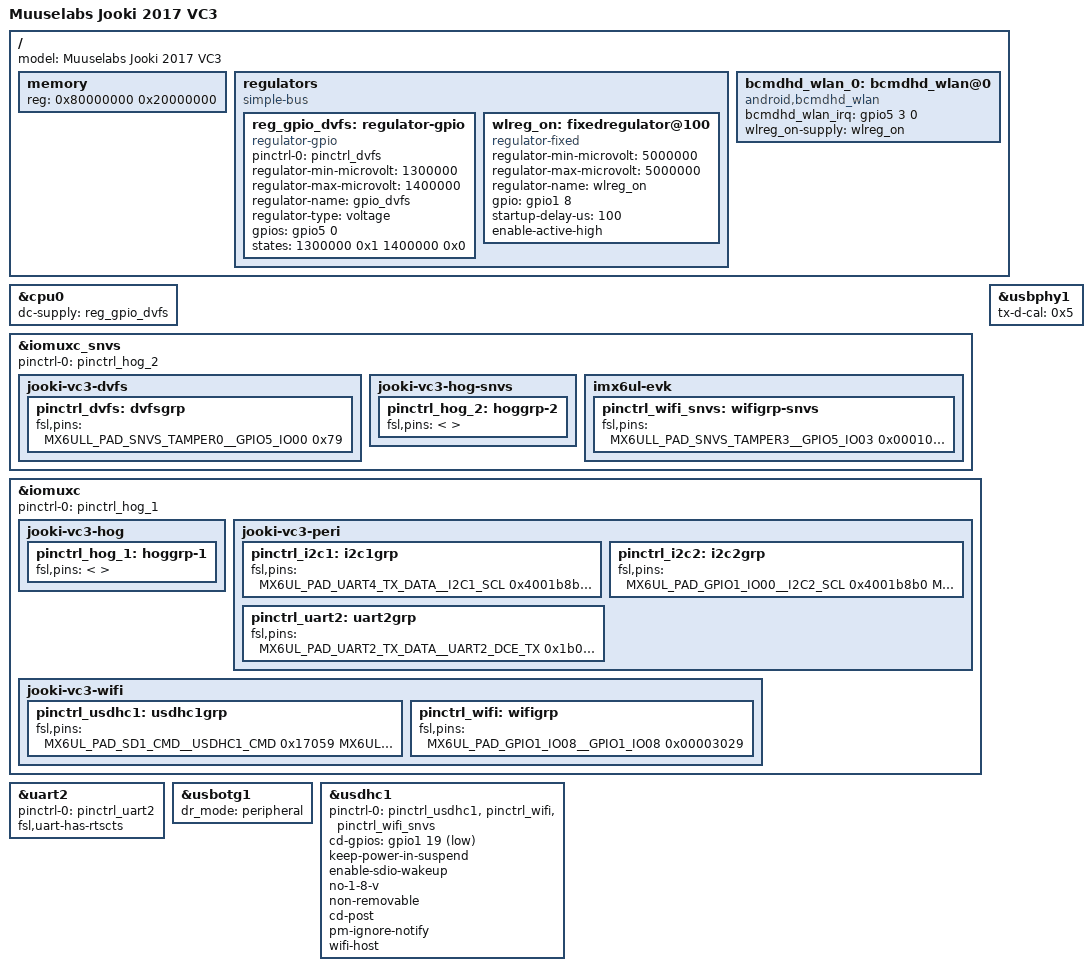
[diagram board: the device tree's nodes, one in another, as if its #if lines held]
/*
 * Copyright (C) 2016 Freescale Semiconductor, Inc.
 * Copyright (C) 2017, Muuselabs NV/SA
 *
 * This program is free software; you can redistribute it and/or modify
 * it under the terms of the GNU General Public License version 2 as
 * published by the Free Software Foundation.
 */


/dts-v1/;

#include <dt-bindings/input/input.h>
#include "imx6ull.dtsi"

#include "ml-jooki-common.dtsi"

/ {
	model = "Muuselabs Jooki 2017 VC3";
	
	// NOTE: the amount of memory can be board-specific
	memory {
		reg = <0x80000000 0x20000000>;
	};
};

/* Dynamic Voltage and Frequency Scaling
 * requires a proper spec of the reg_gpio_dvfs
 * which is board specific in its GPIO assignment
 */
/ {
	regulators {
		compatible = "simple-bus";
		#address-cells = <1>;
		#size-cells = <0>;
		
		reg_gpio_dvfs: regulator-gpio {
			compatible = "regulator-gpio";
			pinctrl-names = "default";
			pinctrl-0 = <&pinctrl_dvfs>;
			regulator-min-microvolt = <1300000>;
			regulator-max-microvolt = <1400000>;
			regulator-name = "gpio_dvfs";
			regulator-type = "voltage";
			// PP: crosschecked sch VC3.0  20170714
			gpios = <&gpio5 0 GPIO_ACTIVE_HIGH>;  
			states = <1300000 0x1 1400000 0x0>;
		};
	};
};

&cpu0 {
	dc-supply = <&reg_gpio_dvfs>;
};

&iomuxc_snvs {
	jooki-vc3-dvfs {
		pinctrl_dvfs: dvfsgrp {
			fsl,pins = <
			MX6ULL_PAD_SNVS_TAMPER0__GPIO5_IO00      0x79 /* PP: crosschecked sch VC3.0  20170714 */
			>;
		};
	};
};

/* HOG / GPIO
 * TODO: what does this stand for?
 */

&iomuxc {
	pinctrl-names = "default";
	pinctrl-0 = <&pinctrl_hog_1>;
	jooki-vc3-hog {
		pinctrl_hog_1: hoggrp-1 {
			fsl,pins = <
			>;
		};
	};
};

&iomuxc_snvs {
	pinctrl-names = "default_snvs";
	pinctrl-0 = <&pinctrl_hog_2>;
	jooki-vc3-hog-snvs {
		pinctrl_hog_2: hoggrp-2 {
			fsl,pins = <
			>;
		};
	};
};

/* Serial interfaces
 */
&iomuxc {
	jooki-vc3-peri {
		pinctrl_i2c1: i2c1grp {
			fsl,pins = <
			MX6UL_PAD_UART4_TX_DATA__I2C1_SCL 0x4001b8b0 /* PP: crosschecked sch VC3.0 20170714 */
			MX6UL_PAD_UART4_RX_DATA__I2C1_SDA 0x4001b8b0 /* PP: crosschecked sch VC3.0  20170714 */
			>;
		};
		
		pinctrl_i2c2: i2c2grp {
			fsl,pins = <
			MX6UL_PAD_GPIO1_IO00__I2C2_SCL  0x4001b8b0 /* PP: crosschecked sch VC3.0  20170714 */
			MX6UL_PAD_GPIO1_IO01__I2C2_SDA  0x4001b8b0 /* PP: crosschecked sch VC3.0  20170714 */
			>;
		};

		pinctrl_uart2: uart2grp {
			fsl,pins = <
			MX6UL_PAD_UART2_TX_DATA__UART2_DCE_TX	0x1b0b1
			MX6UL_PAD_UART2_RX_DATA__UART2_DCE_RX	0x1b0b1
			MX6UL_PAD_UART3_RX_DATA__UART2_DCE_RTS	0x1b0b1
			MX6UL_PAD_UART3_TX_DATA__UART2_DCE_CTS	0x1b0b1
			>;
		};
	};
};

&uart2 {
	pinctrl-names = "default";
	pinctrl-0 = <&pinctrl_uart2>;
	fsl,uart-has-rtscts;
	status = "okay";
};

&usbotg1 {
	dr_mode = "peripheral";
	status = "okay";
};

&usbphy1 {
	tx-d-cal = <0x5>;
};

/* WIFI / BT section */
/ {
	regulators {
		wlreg_on: fixedregulator@100 {
			compatible = "regulator-fixed";
			regulator-min-microvolt = <5000000>;
			regulator-max-microvolt = <5000000>;
			regulator-name = "wlreg_on";
			gpio = <&gpio1 8 0>; /* PP: crosschecked sch VC3.0  20170714 */
			startup-delay-us = <100>;
			enable-active-high;
		};
	};
	
	bcmdhd_wlan_0: bcmdhd_wlan@0 {
		compatible = "android,bcmdhd_wlan";
#ifdef WLAN_OOB
		bcmdhd_wlan_irq = <&gpio5 3 0>;
#endif
		wlreg_on-supply = <&wlreg_on>;
	};
};

&iomuxc {
	jooki-vc3-wifi {
		pinctrl_usdhc1: usdhc1grp {
			fsl,pins = <
			MX6UL_PAD_SD1_CMD__USDHC1_CMD     0x17059
			MX6UL_PAD_SD1_CLK__USDHC1_CLK     0x10071
			MX6UL_PAD_SD1_DATA0__USDHC1_DATA0 0x17059
			MX6UL_PAD_SD1_DATA1__USDHC1_DATA1 0x17059
			MX6UL_PAD_SD1_DATA2__USDHC1_DATA2 0x17059
			MX6UL_PAD_SD1_DATA3__USDHC1_DATA3 0x17059
			>;
		};
		
		pinctrl_wifi: wifigrp {
			fsl,pins = <
			MX6UL_PAD_GPIO1_IO08__GPIO1_IO08          0x00003029 /* WL_REG_ON */   /* PP: crosschecked sch VC3.0  20170714 */
			>;
		};
	};
};

&iomuxc_snvs {
	imx6ul-evk {
		pinctrl_wifi_snvs: wifigrp-snvs {
			fsl,pins = <
#ifdef WLAN_OOB
			MX6ULL_PAD_SNVS_TAMPER3__GPIO5_IO03        0x000100A0 /* WL_HOST_WAKE */   /* PP: crosschecked sch VC3.0  20170714 */
#endif
#ifdef BT_OOB
			MX6ULL_PAD_SNVS_TAMPER1__GPIO5_IO01        0x000100A0 /* BT_HOST_WAKE */   /* PP: crosschecked sch VC3.0  20170714 */
#endif
			>;
		};
	};
};

&usdhc1 {
	pinctrl-names = "default";
	pinctrl-0 = <&pinctrl_usdhc1 &pinctrl_wifi &pinctrl_wifi_snvs>;
	cd-gpios = <&gpio1 19 GPIO_ACTIVE_LOW>;
	keep-power-in-suspend; // FIXME: needed?
	enable-sdio-wakeup; // FIXME: needed?
	no-1-8-v;
	non-removable;
	cd-post; 
	pm-ignore-notify;
	wifi-host; /* add hook for SD card detect mechanism for BCMDHD driver */
	status = "okay";
};

